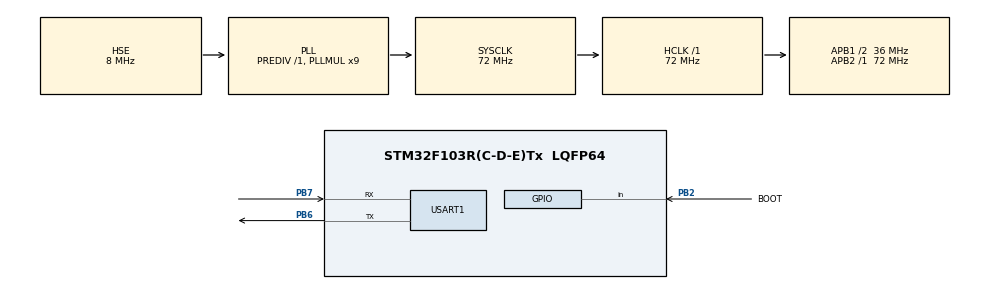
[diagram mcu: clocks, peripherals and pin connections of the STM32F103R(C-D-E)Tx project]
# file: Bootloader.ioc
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Mcu.Family=STM32F1
Mcu.Name=STM32F103R(C-D-E)Tx
Mcu.Package=LQFP64
NVIC.PriorityGroup=NVIC_PRIORITYGROUP_4
PA13.Mode=Serial_Wire
PA13.Signal=SYS_JTMS-SWDIO
PA14.Mode=Serial_Wire
PA14.Signal=SYS_JTCK-SWCLK
PB2.GPIO_Label=BOOT
PB2.GPIO_PuPd=GPIO_NOPULL
PB2.Signal=GPIO_Input
PB6.Mode=Asynchronous
PB6.Signal=USART1_TX
PB7.Mode=Asynchronous
PB7.Signal=USART1_RX
PD0-OSC_IN.Mode=HSE-External-Oscillator
PD0-OSC_IN.Signal=RCC_OSC_IN
PD1-OSC_OUT.Mode=HSE-External-Oscillator
PD1-OSC_OUT.Signal=RCC_OSC_OUT
ProjectManager.HeapSize=0x200
ProjectManager.StackSize=0x400
ProjectManager.TargetToolchain=MDK-ARM V5.32
RCC.AHBFreq_Value=72000000
RCC.APB1CLKDivider=RCC_HCLK_DIV2
RCC.APB1Freq_Value=36000000
RCC.APB1TimFreq_Value=72000000
RCC.APB2Freq_Value=72000000
RCC.APB2TimFreq_Value=72000000
RCC.HCLKFreq_Value=72000000
RCC.PLLMUL=RCC_PLL_MUL9
RCC.PLLSourceVirtual=RCC_PLLSOURCE_HSE
RCC.SYSCLKFreq_VALUE=72000000
RCC.SYSCLKSource=RCC_SYSCLKSOURCE_PLLCLK
RCC.USBFreq_Value=48000000
RCC.USBPrescaler=RCC_USBCLKSOURCE_PLL_DIV1_5
USART1.VirtualMode=VM_ASYNC
board=custom

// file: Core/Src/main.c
/* USER CODE BEGIN Header */
/**
  ******************************************************************************
  * @file           : main.c
  * @brief          : Main program body
  ******************************************************************************
  * @attention
  *
  * Copyright (c) 2023 STMicroelectronics.
  * All rights reserved.
  *
  * This software is licensed under terms that can be found in the LICENSE file
  * in the root directory of this software component.
  * If no LICENSE file comes with this software, it is provided AS-IS.
  *
  ******************************************************************************
  */
/* USER CODE END Header */
#include "main.h"
#include "usart.h"
#include "gpio.h"

/* USER CODE BEGIN Includes */
#include "tracelog.h"
#include "fatfs.h"
#include "memery.h"
#include "ff.h"
#include "menu.h"
/* USER CODE END Includes */

void SystemClock_Config(void);

/* USER CODE BEGIN 0 */

#define APP_BIN_FILENAME "1:bin/PALK.bin"

void Jump2App()
{
	static uint32_t jump_addr;

    // Jump to the app code
	jump_addr = *((__IO uint32_t*)(APP_ADDR+4u));

	// Disable all interrupts
	NVIC->ICER[0] = 0xFFFFFFFF;
	NVIC->ICER[1] = 0xFFFFFFFF;
	NVIC->ICER[2] = 0xFFFFFFFF;

	NVIC->ICPR[0] = 0xFFFFFFFF;
	NVIC->ICPR[1] = 0xFFFFFFFF;
	NVIC->ICPR[2] = 0xFFFFFFFF;

	/* deactivate SysTick */
	SysTick->CTRL = 0;

	/* Change the main stack pointer. */
	SCB->VTOR = APP_ADDR;
	__set_MSP((*(__IO uint32_t*)APP_ADDR));

	((void (*) (void)) (jump_addr)) ();
 }

static FIL fp;

uint8_t Check_Bin(uint32_t size)
{
	uint32_t fsize = f_size(&fp);
	uint32_t fdata,sdata;
	UINT readcount = 0;
	uint32_t addr = APP_ADDR;

	if(fsize != size)
		return false;

	f_lseek(&fp, 0);

	while(0 == f_eof(&fp))
	{
		sdata = flash_read_word(addr);
		f_read(&fp, (uint8_t*)&fdata, 4, &readcount);
		if(4 == readcount)
		{
			addr+=4;
			if(sdata != fdata)
				return false;
		}
		else
		{
			return f_eof(&fp);
		}
	}

	return true;
}

void SaveCurrentFirmware()
{
	uint32_t buffer;
	uint32_t addr = 0;

	while(addr<(FRAMEWARE_SIZE_MAX))
	{
		buffer = flash_read_word(APP_ADDR+addr);
		if(0 == (addr%STM32_SECTOR_SIZE))
		{
			flash_erase(OLD_FRAMEWARE_ADDR+addr);
		}
		flash_write_word(OLD_FRAMEWARE_ADDR+addr,buffer);
		addr+=4;
	}
}

void LoadOldFirmware()
{
	uint32_t buffer;
	uint32_t addr = 0;

	while(addr<(FRAMEWARE_SIZE_MAX))
	{
		buffer = flash_read_word(OLD_FRAMEWARE_ADDR+addr);
		if(0 == (addr%STM32_SECTOR_SIZE))
		{
			flash_erase(APP_ADDR+addr);
		}
		flash_write_word(APP_ADDR+addr,buffer);
		addr+=4;
	}
}

uint8_t LoadBinFile()
{
	uint32_t buffer;
	UINT readcount = 0;
	uint32_t addr = APP_ADDR;
	uint8_t ret;
	TRACELOG_DEBUG("Loading!");
	while(FR_OK == f_read(&fp, (uint8_t*)&buffer, 4, &readcount))
	{
		if(readcount)
		{
			if(0 == (addr%STM32_SECTOR_SIZE))
			{
				flash_erase(addr);
			}
			flash_write_word(addr, buffer);
			addr += readcount;

			if(f_eof(&fp) || (addr%4))
			{
				break;
			}
		}
		else
		{
			break;
		}
	}
	TRACELOG_DEBUG("Load bin file finish!");

	ret = Check_Bin(addr-APP_ADDR);
	if(false == ret)
	{
		TRACELOG_ERROR("Check the flash fail!");
	}
	else
	{
		TRACELOG_DEBUG("Check the flash success!");
	}

	f_close(&fp);
	f_rmdir(APP_BIN_FILENAME);

	return ret;

}

uint8_t CheckBinExist()
{
	FRESULT f_res;

	if(0 == IntFlash_Mount())
	{
		TRACELOG_ERROR("Mount fs fail!");
		return false;
	}

	f_res = f_open(&fp,APP_BIN_FILENAME,FA_OPEN_EXISTING|FA_READ);
	if(FR_OK != f_res)
	{
		TRACELOG_ERROR("Open bin file fail!");
		return false;
	}
	return true;
}

void DeInitAll()
{
	IntFlash_Unmount();
	MX_USART1_UART_DeInit();
	MX_GPIO_DeInit();
	HAL_DeInit();
}

void MSC_Boot()
{
	if(CheckBinExist())
	{
		SaveCurrentFirmware();
		if(0 == LoadBinFile())
		{
			TRACELOG_DEBUG("Restore the previous firmware!");
			LoadOldFirmware();
		}
	}
}

void Ymodem_Boot()
{
	Main_Menu();
}

/* USER CODE END 0 */

int main(void)
{

  /* MCU Configuration--------------------------------------------------------*/

  /* Reset of all peripherals, Initializes the Flash interface and the Systick. */
  HAL_Init();

  /* Configure the system clock */
  SystemClock_Config();

  /* Initialize all configured peripherals */
  MX_GPIO_Init();
  MX_USART1_UART_Init();
  /* USER CODE BEGIN 2 */
	TRACELOG_DEBUG("BootLoader start!");
  	if(HAL_GPIO_ReadPin(BOOT_GPIO_Port, BOOT_Pin))//boot0=0 boot1=1 ??��?��??��bootloader
	{
		Ymodem_Boot();
	}
	else//boot0=0 boot1=0 ??��?U?��bootloader
	{
		if(MEM_FlagBit_IsEnabled(MEM_FLAG_BOOTLOADER))
		{//1��?t?��APP��?msc?�꨺?????��?flash��??��bootloader����?��??��?APP_ADDR
			MEM_FlagBit_Reset(MEM_FLAG_BOOTLOADER);
			MSC_Boot();
		}
	}

	DeInitAll();
	Jump2App();
	//
	MX_GPIO_Init();
  	MX_USART1_UART_Init();

  /* USER CODE END 2 */

  /* Infinite loop */
  /* USER CODE BEGIN WHILE */
  while (1)
  {
  	TRACELOG_ERROR("BootLoader fail...!!!");
  	HAL_Delay(10000);
    /* USER CODE END WHILE */

  }
}

void SystemClock_Config(void)
{
  RCC_OscInitTypeDef RCC_OscInitStruct = {0};
  RCC_ClkInitTypeDef RCC_ClkInitStruct = {0};

  /** Initializes the RCC Oscillators according to the specified parameters
  * in the RCC_OscInitTypeDef structure.
  */
  RCC_OscInitStruct.OscillatorType = RCC_OSCILLATORTYPE_HSE;
  RCC_OscInitStruct.HSEState = RCC_HSE_ON;
  RCC_OscInitStruct.HSEPredivValue = RCC_HSE_PREDIV_DIV1;
  RCC_OscInitStruct.HSIState = RCC_HSI_ON;
  RCC_OscInitStruct.PLL.PLLState = RCC_PLL_ON;
  RCC_OscInitStruct.PLL.PLLSource = RCC_PLLSOURCE_HSE;
  RCC_OscInitStruct.PLL.PLLMUL = RCC_PLL_MUL9;
  if (HAL_RCC_OscConfig(&RCC_OscInitStruct) != HAL_OK)
  {
    Error_Handler();
  }

  /** Initializes the CPU, AHB and APB buses clocks
  */
  RCC_ClkInitStruct.ClockType = RCC_CLOCKTYPE_HCLK|RCC_CLOCKTYPE_SYSCLK
                              |RCC_CLOCKTYPE_PCLK1|RCC_CLOCKTYPE_PCLK2;
  RCC_ClkInitStruct.SYSCLKSource = RCC_SYSCLKSOURCE_PLLCLK;
  RCC_ClkInitStruct.AHBCLKDivider = RCC_SYSCLK_DIV1;
  RCC_ClkInitStruct.APB1CLKDivider = RCC_HCLK_DIV2;
  RCC_ClkInitStruct.APB2CLKDivider = RCC_HCLK_DIV1;

  if (HAL_RCC_ClockConfig(&RCC_ClkInitStruct, FLASH_LATENCY_2) != HAL_OK)
  {
    Error_Handler();
  }
}

void Error_Handler(void)
{
  __disable_irq();
  while (1)
  {
  }
}
